# GD32F10x_HD register map
File version: 1.0
CPU: CM3 r2p1, little endian, no MPU, no FPU, 4 interrupt priority bits
Registers are 32-bit, read-write, reset 0x0 unless marked. A register's access mark holds for its fields unless they carry their own. Offsets are from the block's base; [hi:lo] are bit positions; {n}, {i} and the like mark numbered series; 'fields as' and 'values as' point back to an identical list.

## DMA0 — DMA controller
Base 0x40020000
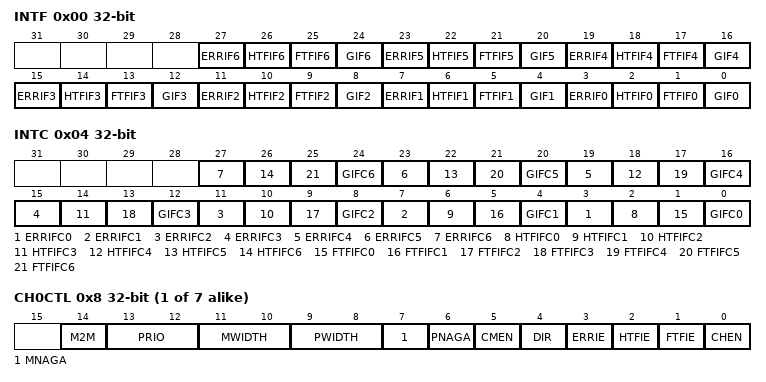
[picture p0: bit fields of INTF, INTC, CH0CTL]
0x00 INTF ro — Interrupt flag register
  [4n+3] ERRIF{n} (n=0..6) — Error flag of channel {n}
  [4n+2] HTFIF{n} (n=0..6) — Half transfer finish flag of channel {n}
  [4n+1] FTFIF{n} (n=0..6) — Full Transfer finish flag of channe {n}
  [4n] GIF{n} (n=0..6) — Global interrupt flag of channel {n}
0x04 INTC wo — Interrupt flag clear register
  [4n+3] ERRIFC{n} (n=0..6) — Clear bit for error flag of channel {n}
  [4n+2] HTFIFC{n} (n=0..6) — Clear bit for half transfer finish flag of channel {n}
  [4n+1] FTFIFC{n} (n=0..6) — Clear bit for full transfer finish flag of channel {n}
  [4n] GIFC{n} (n=0..6) — Clear global interrupt flag of channel {n}
{0x8+0x14*i} CH{i}CTL (i=0..6) — Channel {i} control register
  [14] M2M — Memory to Memory Mode
  [13:12] PRIO — Priority level
  [11:10] MWIDTH — Transfer data size of memory
  [9:8] PWIDTH — Transfer data size of peripheral
  [7] MNAGA — Next address generation algorithm of memory
  [6] PNAGA — Next address generation algorithm of peripheral
  [5] CMEN — Circular mode enable
  [4] DIR — Transfer direction
  [3] ERRIE — Enable bit for channel error interrupt
  [2] HTFIE — Enable bit for channel half transfer finish interrupt
  [1] FTFIE — Enable bit for channel full transfer finish interrupt
  [0] CHEN — Channel enable
{0xC+0x14*i} CH{i}CNT (i=0..6) — Channel {i} counter register
  [15:0] CNT — Transfer counter
{0x10+0x14*i} CH{i}PADDR (i=0..6) — Channel {i} peripheral base address register
  [31:0] PADDR — Peripheral base address
{0x14+0x14*i} CH{i}MADDR (i=0..6) — Channel {i} memory base address register
  [31:0] MADDR — Memory base address

## DMA1 — Direct memory access controller
Base 0x40020000
Registers as DMA0, without CH5CTL, CH5CNT, CH5PADDR, CH5MADDR, CH6CTL, CH6CNT, CH6PADDR, CH6MADDR.

## EXTI — External interrupt/event controller
Base 0x40010400
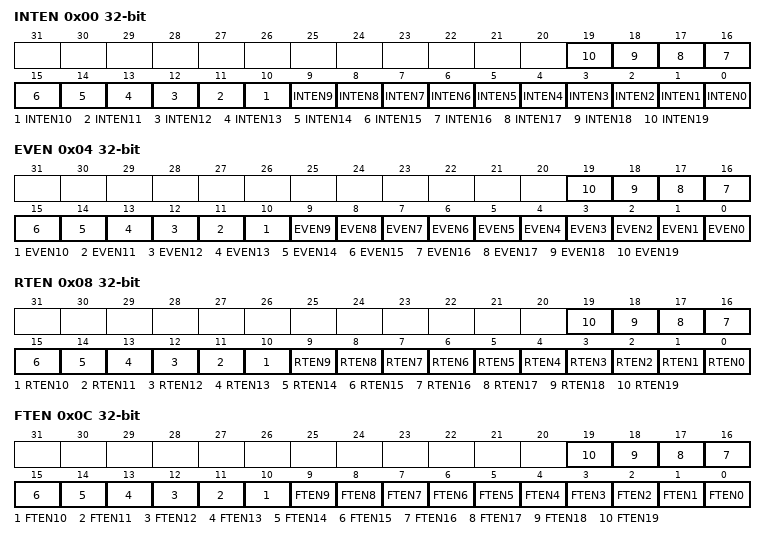
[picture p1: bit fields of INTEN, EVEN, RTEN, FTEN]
0x00 INTEN — Interrupt enable register (EXTI_INTEN)
  [n] INTEN{n} (n=0..19) — Enable Interrupt on line {n}
0x04 EVEN — Event enable register (EXTI_EVEN)
  [n] EVEN{n} (n=0..19) — Enable Event on line {n}
0x08 RTEN — Rising Edge Trigger Enable register (EXTI_RTEN)
  [n] RTEN{n} (n=0..19) — Rising edge trigger enable of line {n}
0x0C FTEN — Falling Egde Trigger Enable register (EXTI_FTEN)
  [n] FTEN{n} (n=0..19) — Falling edge trigger enable of line {n}
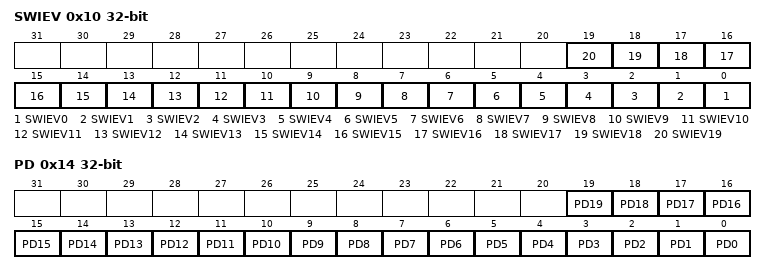
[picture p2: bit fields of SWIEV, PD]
0x10 SWIEV — Software interrupt event register (EXTI_SWIEV)
  [n] SWIEV{n} (n=0..19) — Interrupt/Event software trigger on line {n}
0x14 PD — Pending register (EXTI_PD)
  [n] PD{n} (n=0..19) — Interrupt pending status of line {n}

## FMC
Base 0x40022000
0x00 WS — wait state counter register
  [2:0] WSCNT
0x04 KEY0 wo — Unlock key register 0
  [31:0] KEY — FMC_CTL0 unlock key
0x08 OBKEY wo — Option byte unlock key register
  [31:0] OBKEY — FMC_ CTL0 option byte operation unlock register
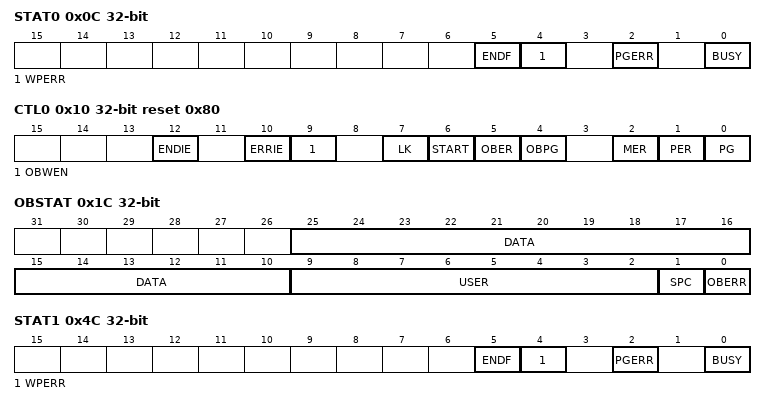
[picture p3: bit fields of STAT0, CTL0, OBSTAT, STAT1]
0x0C STAT0 access per field — Status register 0
  [5] ENDF rw — End of operation flag bit
  [4] WPERR rw — Erase/Program protection error flag bit
  [2] PGERR rw — Program error flag bit
  [0] BUSY ro — The flash is busy bit
0x10 CTL0 reset 0x80 — Control register 0
  [12] ENDIE — End of operation interrupt enable bit
  [10] ERRIE — Error interrupt enable bit
  [9] OBWEN — Option byte erase/program enable bit
  [7] LK — FMC_CTL0 lock bit
  [6] START — Send erase command to FMC bit
  [5] OBER — Option bytes erase command bit
  [4] OBPG — Option bytes program command bit
  [2] MER — Main flash mass erase for bank0 command bit
  [1] PER — Main flash page erase for bank0 command bit
  [0] PG — Main flash program for bank0 command bit
0x14 ADDR0 wo — Address register 0
  [31:0] ADDR — Flash erase/program command address bits
0x1C OBSTAT ro — Option byte status register
  [25:10] DATA — Store DATA[15:0] of option bytes block after system reset
  [9:2] USER — Store USER of option bytes block after system reset
  [1] SPC — Option bytes security protection code
  [0] OBERR — Option bytes read error bit
0x20 WP ro — Erase/Program Protection register
  [31:0] WP — Store WP[31:0] of option bytes block after system reset
0x44 KEY1 wo — Unlock key register 1
  [31:0] KEY — FMC_CTL1 unlock register
0x4C STAT1 access per field — Status register 1
  fields as STAT0
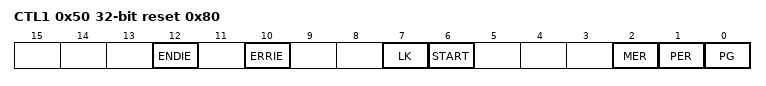
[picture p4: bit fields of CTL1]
0x50 CTL1 reset 0x80 — Control register 1
  [12] ENDIE — End of operation interrupt enable bit
  [10] ERRIE — Error interrupt enable bit
  [7] LK — FMC_CTL1 lock bit
  [6] START — Send erase command to FMC bit
  [2] MER — Main flash mass erase for bank1 command bit
  [1] PER — Main flash page erase for bank1 command bit
  [0] PG — Main flash program for bank1 command bit
0x54 ADDR1 wo — Address register 1
  [31:0] ADDR — Flash erase/program command address bits
0xFC WSEN — Wait state enable register
  [0] WSEN — FMC wait state enable register
0x100 PID ro — Product ID register
  [31:0] PID — Product reserved ID code register
